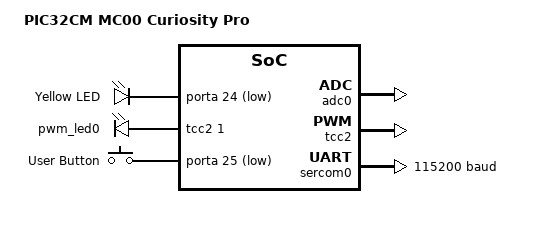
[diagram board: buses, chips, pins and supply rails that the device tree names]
/* Copyright (c) 2024 Microchip Technology Inc. and its subsidiaries.
 *
 * SPDX-License-Identifier: Apache-2.0
 */

/dts-v1/;
#include <microchip/pic32cm_mc00/pic32cm1216mc00032.dtsi>
#include <microchip/pic32cm_mc00/pic32cm_mc00-dma-trigsrc.h>
#include "pic32cm_mc00_cpro-pinctrl.dtsi"
#include <zephyr/dt-bindings/input/input-event-codes.h>

/ {
	model = "PIC32CM MC00 Curiosity Pro";
	compatible = "microchip,pic32cm_mc00_cpro";

	chosen {
		zephyr,console = &sercom0;
		zephyr,shell-uart = &sercom0;
		zephyr,sram = &sram0;
		zephyr,flash = &flash0;
	};

	/* These aliases are provided for compatibility with samples */
	aliases {
		led0 = &led0;
		pwm-led0 = &pwm_led0;
		sw0 = &user_button;
		i2c-0 = &sercom1;
	};

	leds {
		compatible = "gpio-leds";
		led0: led_0 {
			gpios = <&porta 24 GPIO_ACTIVE_LOW>;
			label = "Yellow LED";
		};
	};

	pwmleds {
		compatible = "pwm-leds";
		pwm_led0: pwm_led_0 {
			pwms = <&tcc2 1 PWM_MSEC(20)>;
		};
	};

	buttons {
		compatible = "gpio-keys";
		user_button: button_0 {
			gpios = <&porta 25 (GPIO_PULL_UP | GPIO_ACTIVE_LOW)>;
			label = "User Button";
			zephyr,code = <INPUT_KEY_0>;
		};
	};

};

&cpu0 {
	clock-frequency = <48000000>;
};

&adc0 {
	status = "okay";
	pinctrl-0 = <&adc0_default>;
	pinctrl-names = "default";
};

&tcc2 {
	status = "okay";
	compatible = "microchip,tcc-u2213-pwm";
	prescaler = <256>;
	#pwm-cells = <2>;

	pinctrl-0 = <&pwm_default>;
	pinctrl-names = "default";
};

&sercom0 {
	status = "okay";
	compatible = "microchip,sercom-u2201-uart";
	current-speed = <115200>;
	rxpo = <3>;
	txpo = <1>;

	dmas = <&dmac 1 DMAC_CHCTRLB_TRIGSRC_SERCOM0_TX_Val>, <&dmac 2 DMAC_CHCTRLB_TRIGSRC_SERCOM0_RX_Val>;
	dma-names = "tx", "rx";

	pinctrl-0 = <&sercom0_uart_default>;
	pinctrl-names = "default";
};

&sercom1 {
	status = "disabled";
	compatible = "microchip,sercom-u2201-i2c";
	clock-frequency = <I2C_BITRATE_FAST>;
	#address-cells = <1>;
	#size-cells = <0>;

	pinctrl-0 = <&sercom1_i2c_default>;
	pinctrl-names = "default";
};

&sercom2 {
	status = "disabled";
	compatible = "microchip,sercom-u2201-uart";
	current-speed = <115200>;
	rxpo = <1>;
	txpo = <0>;

	pinctrl-0 = <&sercom2_uart_default>;
	pinctrl-names = "default";
};

&sercom4 {
	status = "disabled";
	compatible = "microchip,sercom-u2201-uart";
	current-speed = <115200>;
	rxpo = <3>;
	txpo = <1>;
	pinctrl-0 = <&sercom4_uart_default>;
	pinctrl-names = "default";
};

&flash0 {
	partitions {
		compatible = "fixed-partitions";
		#address-cells = <1>;
		#size-cells = <1>;

		/*
		 * The final 16 KiB is reserved for the application.
		 * Storage partition will be used by FCB/LittleFS/NVS
		 * if enabled.
		 */
		storage_partition: partition@3c000 {
			label = "storage";
			reg = <0x0003c000 0x00004000>;
		};
	};
};

